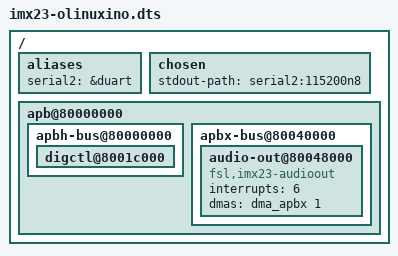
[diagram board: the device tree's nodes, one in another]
/* $NetBSD: imx23-olinuxino.dts,v 1.3 2026/02/01 11:31:27 yurix Exp $ */

/*-
 * Copyright (c) 2025 The NetBSD Foundation, Inc.
 * All rights reserved.
 *
 * This code is derived from software contributed to The NetBSD Foundation
 * by Yuri Honegger.
 *
 * Redistribution and use in source and binary forms, with or without
 * modification, are permitted provided that the following conditions
 * are met:
 * 1. Redistributions of source code must retain the above copyright
 *    notice, this list of conditions and the following disclaimer.
 * 2. Redistributions in binary form must reproduce the above copyright
 *    notice, this list of conditions and the following disclaimer in the
 *    documentation and/or other materials provided with the distribution.
 *
 * THIS SOFTWARE IS PROVIDED BY THE NETBSD FOUNDATION, INC. AND CONTRIBUTORS
 * ``AS IS'' AND ANY EXPRESS OR IMPLIED WARRANTIES, INCLUDING, BUT NOT LIMITED
 * TO, THE IMPLIED WARRANTIES OF MERCHANTABILITY AND FITNESS FOR A PARTICULAR
 * PURPOSE ARE DISCLAIMED.  IN NO EVENT SHALL THE FOUNDATION OR CONTRIBUTORS
 * BE LIABLE FOR ANY DIRECT, INDIRECT, INCIDENTAL, SPECIAL, EXEMPLARY, OR
 * CONSEQUENTIAL DAMAGES (INCLUDING, BUT NOT LIMITED TO, PROCUREMENT OF
 * SUBSTITUTE GOODS OR SERVICES; LOSS OF USE, DATA, OR PROFITS; OR BUSINESS
 * INTERRUPTION) HOWEVER CAUSED AND ON ANY THEORY OF LIABILITY, WHETHER IN
 * CONTRACT, STRICT LIABILITY, OR TORT (INCLUDING NEGLIGENCE OR OTHERWISE)
 * ARISING IN ANY WAY OUT OF THE USE OF THIS SOFTWARE, EVEN IF ADVISED OF THE
 * POSSIBILITY OF SUCH DAMAGE.
 */

#include "../../../external/gpl2/dts/dist/arch/arm/boot/dts/nxp/mxs/imx23-olinuxino.dts"

/ {
	aliases {
		serial2 = &duart;
	};

	chosen {
		stdout-path = "serial2:115200n8";
	};

	apb@80000000 {
		apbh-bus@80000000 {
			digctl@8001c000 {
				status = "okay";
			};
		};

		apbx-bus@80040000 {
			audio-out@80048000 {
				compatible = "fsl,imx23-audioout";
				interrupts = <6>;
				dmas = <&dma_apbx 1>;
				dma-names = "tx";
				status = "okay";
			};
		};
	};
};
